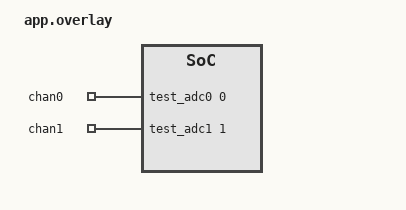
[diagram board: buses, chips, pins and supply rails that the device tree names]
/*
 * Copyright (c) 2026 Nordic Semiconductor ASA
 *
 * SPDX-License-Identifier: Apache-2.0
 */

#include <zephyr/dt-bindings/adc/adc.h>

/ {
	zephyr,user {
		io-channels = <&test_adc0 0>, <&test_adc1 1>;
		io-channel-names = "chan0", "chan1";
	};

	test_adc0: test_adc0 {
		compatible = "vnd,adc";
		#address-cells = <1>;
		#size-cells = <0>;
		#io-channel-cells = <1>;

		channel@0 {
			reg = <0>;
			zephyr,gain = "ADC_GAIN_1";
			zephyr,reference = "ADC_REF_INTERNAL";
			zephyr,acquisition-time = <ADC_ACQ_TIME_DEFAULT>;
			zephyr,input-positive = <0>;
		};
	};

	test_adc1: test_adc1 {
		compatible = "vnd,adc";
		#address-cells = <1>;
		#size-cells = <0>;
		#io-channel-cells = <1>;

		channel@1 {
			reg = <1>;
			zephyr,gain = "ADC_GAIN_1";
			zephyr,reference = "ADC_REF_INTERNAL";
			zephyr,acquisition-time = <ADC_ACQ_TIME_DEFAULT>;
			zephyr,input-positive = <1>;
		};
	};
};
